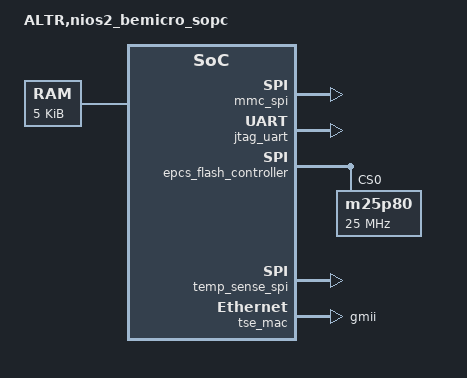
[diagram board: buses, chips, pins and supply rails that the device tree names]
/*
 * This devicetree is generated by sopc2dts
 * Sopc2dts is written by Walter Goossens <waltergoossens@home.nl>
 * in cooperation with the nios2 community <Nios2-dev@sopc.et.ntust.edu.tw>
 */
/dts-v1/;
/ {
	model = "ALTR,nios2_bemicro_sopc";
	compatible = "ALTR,nios2_bemicro_sopc";
	#address-cells = <1>;
	#size-cells = <1>;
	cpus {
		#address-cells = <1>;
		#size-cells = <0>;
		cpu_0: cpu@0x0 {
			device_type = "cpu";
			compatible = "ALTR,nios2-10.1";
			reg = <0>;
			interrupt-controller;
			#interrupt-cells = <1>;
			clock-frequency = <100000000>;	//embeddedsw.CMacro.CPU_FREQ type NUMBER
			dcache-line-size = <32>;	//embeddedsw.CMacro.DCACHE_LINE_SIZE type NUMBER
			icache-line-size = <32>;	//embeddedsw.CMacro.ICACHE_LINE_SIZE type NUMBER
			dcache-size = <4096>;	//embeddedsw.CMacro.DCACHE_SIZE type NUMBER
			icache-size = <8192>;	//embeddedsw.CMacro.ICACHE_SIZE type NUMBER
			ALTR,implementation = "fast";	//embeddedsw.CMacro.CPU_IMPLEMENTATION type STRING
			ALTR,pid-num-bits = <8>;	//embeddedsw.CMacro.PROCESS_ID_NUM_BITS type NUMBER
			ALTR,tlb-num-ways = <16>;	//embeddedsw.CMacro.TLB_NUM_WAYS type NUMBER
			ALTR,tlb-num-entries = <256>;	//embeddedsw.CMacro.TLB_NUM_ENTRIES type NUMBER
			ALTR,tlb-ptr-sz = <8>;	//embeddedsw.CMacro.TLB_PTR_SZ type NUMBER
			ALTR,has-div;	//embeddedsw.CMacro.HARDWARE_DIVIDE_PRESENT type NUMBER
			ALTR,has-mul;	//embeddedsw.CMacro.HARDWARE_MULTIPLY_PRESENT type NUMBER
			ALTR,reset-addr = <0xc880a000>;	//embeddedsw.CMacro.RESET_ADDR type NUMBER
			ALTR,fast-tlb-miss-addr = <0xc0002000>;	//embeddedsw.CMacro.FAST_TLB_MISS_EXCEPTION_ADDR type NUMBER
			ALTR,exception-addr = <0xd0000020>;	//embeddedsw.CMacro.EXCEPTION_ADDR type NUMBER
		};
	};
	memory@0 {
		device_type = "memory";
		reg = <0x00001000 0x00000400
			0x00002000 0x00001000>;
	};
	sopc@0 {
		ranges ;
		#address-cells = <1>;
		#size-cells = <1>;
		device_type = "soc";
		compatible = "ALTR,avalon","simple-bus";
		bus-frequency = < 100000000 >;
		//Port instruction_master of cpu_0
		mobile_ddr_pipe2: bridge@0x10000000 {
			compatible = "ALTR,avalon-10.1","simple-bus";
			reg = < 0x10000000 0x4000000>;
			#address-cells = <1>;
			#size-cells = <1>;
			ranges = <0x00000000 0x10000000 0x04000000>;

			//Port m1 of mobile_ddr_pipe2
			mobile_ddr_sdram: memory@0x0 {
				device_type = "memory";
				compatible = "ALTR,altmemddr-5.4";
				reg = < 0x0 0x4000000>;
			}; //end memory (mobile_ddr_sdram)

		}; //end bridge (mobile_ddr_pipe2)

		mmc_spi: spi@0x0 {
			compatible = "ALTR,spi-10.1","ALTR,spi-1.0";
			reg = < 0x0 0x20>;
			interrupt-parent = < &cpu_0 >;
			interrupts = < 10 >;
		}; //end spi (mmc_spi)

		slow_periph_bridge: bridge@0x8800000 {
			compatible = "ALTR,avalon-10.1","simple-bus";
			reg = < 0x8800000 0x10000>;
			#address-cells = <1>;
			#size-cells = <1>;
			ranges = <0x00001000 0x08801000 0x00000020
				0x00002000 0x08802000 0x00000010
				0x00003000 0x08803000 0x00000010
				0x00005000 0x08805000 0x00000008
				0x00006000 0x08806000 0x00000008
				0x00004000 0x08804000 0x00000010
				0x00007000 0x08807000 0x00000010
				0x00008000 0x08808000 0x00000010
				0x00009000 0x08809000 0x00000100
				0x0000A000 0x0880A000 0x00000800
				0x0000B000 0x0880B000 0x00000010
				0x0000C000 0x0880C000 0x00000010
				0x0000D000 0x0880D000 0x00000010
				0x0000E000 0x0880E000 0x00000010
				0x0000F000 0x0880F000 0x00000020>;

			//Port m1 of slow_periph_bridge
			sys_timer: timer@0x1000 {
				compatible = "ALTR,timer-10.1","ALTR,timer-1.0";
				reg = < 0x1000 0x20>;
				interrupt-parent = < &cpu_0 >;
				interrupts = < 3 >;
				clock-frequency = <60000000>;
			}; //end timer (sys_timer)

			led_pio: gpio@0x2000 {
				compatible = "ALTR,pio-10.1","ALTR,pio-1.0";
				reg = < 0x2000 0x10>;
				width = <8>;	//width type NUMBER
				resetvalue = <0>;	//resetValue type NUMBER
			}; //end gpio (led_pio)

			dipsw_pio: gpio@0x3000 {
				compatible = "ALTR,pio-10.1","ALTR,pio-1.0";
				reg = < 0x3000 0x10>;
				width = <2>;	//width type NUMBER
				resetvalue = <0>;	//resetValue type NUMBER
			}; //end gpio (dipsw_pio)

			jtag_uart: serial@0x5000 {
				compatible = "ALTR,juart-10.1","ALTR,juart-1.0";
				reg = < 0x5000 0x8>;
				interrupt-parent = < &cpu_0 >;
				interrupts = < 5 >;
			}; //end serial (jtag_uart)

			sysid: sysid@0x6000 {
				compatible = "ALTR,sysid-10.1","ALTR,sysid-1.0";
				reg = < 0x6000 0x8>;
			}; //end sysid (sysid)

			user_pio_pushbtn: gpio@0x4000 {
				compatible = "ALTR,pio-10.1","ALTR,pio-1.0";
				reg = < 0x4000 0x10>;
				interrupt-parent = < &cpu_0 >;
				interrupts = < 7 >;
				width = <1>;	//width type NUMBER
				resetvalue = <0>;	//resetValue type NUMBER
			}; //end gpio (user_pio_pushbtn)

			nENET_reg_reset: gpio@0x7000 {
				compatible = "ALTR,pio-10.1","ALTR,pio-1.0";
				reg = < 0x7000 0x10>;
				width = <1>;	//width type NUMBER
				resetvalue = <1>;	//resetValue type NUMBER
			}; //end gpio (nENET_reg_reset)

			product_info_0: unknown@0x8000 {
				compatible = "unknown,unknown-1.0";
				reg = < 0x8000 0x10>;
			}; //end unknown (product_info_0)

			remote_update_blk: altremote@0x9000 {
				compatible = "ALTR,remote-10.1","ALTR,remote-1.0";
				reg = < 0x9000 0x100>;
			}; //end altremote (remote_update_blk)

			epcs_flash_controller: spi@0xa400 {
				#address-cells = <1>;
				#size-cells = <0>;
				compatible = "ALTR,spi-10.1","ALTR,spi-1.0";
				reg = < 0xa400 0x800>;
				interrupt-parent = < &cpu_0 >;
				interrupts = < 11 >;

				m25p80@0 {
					compatible = "m25p80";
					spi-max-frequency = <25000000>;
					reg = <0>;
				};
			}; //end spi (epcs_flash_controller)

			EC_GPIO_1: gpio@0xb000 {
				compatible = "ALTR,pio-10.1","ALTR,pio-1.0";
				reg = < 0xb000 0x10>;
				width = <32>;	//width type NUMBER
				resetvalue = <0>;	//resetValue type NUMBER
			}; //end gpio (EC_GPIO_1)

			EC_GPIO_2: gpio@0xc000 {
				compatible = "ALTR,pio-10.1","ALTR,pio-1.0";
				reg = < 0xc000 0x10>;
				width = <32>;	//width type NUMBER
				resetvalue = <0>;	//resetValue type NUMBER
			}; //end gpio (EC_GPIO_2)

			nRESET_EXP: gpio@0xd000 {
				compatible = "ALTR,pio-10.1","ALTR,pio-1.0";
				reg = < 0xd000 0x10>;
				width = <1>;	//width type NUMBER
				resetvalue = <0>;	//resetValue type NUMBER
			}; //end gpio (nRESET_EXP)

			EXP_PRESENT: gpio@0xe000 {
				compatible = "ALTR,pio-10.1","ALTR,pio-1.0";
				reg = < 0xe000 0x10>;
				width = <1>;	//width type NUMBER
				resetvalue = <0>;	//resetValue type NUMBER
			}; //end gpio (EXP_PRESENT)

			temp_sense_spi: spi@0xf000 {
				compatible = "ALTR,spi-10.1","ALTR,spi-1.0";
				reg = < 0xf000 0x20>;
				interrupt-parent = < &cpu_0 >;
				interrupts = < 12 >;
			}; //end spi (temp_sense_spi)

		}; //end bridge (slow_periph_bridge)

		//Port tightly_coupled_instruction_master_0 of cpu_0
		//Port data_master of cpu_0
		ethernet_sd_bridge: bridge@0x8000000 {
			compatible = "ALTR,avalon-10.1","simple-bus";
			reg = < 0x8000000 0x4000>;
			#address-cells = <1>;
			#size-cells = <1>;
			ranges = <0x00002000 0x08002000 0x00000400
				0x00001000 0x08001000 0x00000040
				0x00003000 0x08003000 0x00000040
				0x00000000 0x08000000 0x00001000>;

			//Port m1 of ethernet_sd_bridge
			tse_mac: ethernet@0x2000 {
				compatible = "ALTR,tse-10.1","ALTR,tse-1.0";
				reg = < 0x2000 0x400 0x3000 0x40 0x1000 0x40 0x0 0x1000>;
				interrupt-parent = < &cpu_0 >;
				interrupts = < 2 1 >;
				ALTR,rx-fifo-depth = <1024>;	//embeddedsw.CMacro.RECEIVE_FIFO_DEPTH type NUMBER
				ALTR,tx-fifo-depth = <1024>;	//embeddedsw.CMacro.TRANSMIT_FIFO_DEPTH type NUMBER
				address-bits = <48>;
				max-frame-size = <1518>;
				local-mac-address = [ 00 07 ED 01 02 03 ];
				phy-mode = "gmii";
				ALTR,mii-id = <0>;
			}; //end ethernet (tse_mac)

		}; //end bridge (ethernet_sd_bridge)

		//Port tightly_coupled_data_master_0 of cpu_0
	}; //sopc
	chosen {
		bootargs = "debug console=ttyJ0,115200";
	};
};
